# scb register map
Vendor: Texas Instruments
Peripheral module from a debugger description file (folder MSP432).
Registers are 32-bit, read-write, no defined reset value unless marked. A register's access mark holds for its fields unless they carry their own. Offsets are as the file gives them; lines under a group give offsets from that group; [hi:lo] are bit positions; {n}, {i} and the like mark numbered series; 'fields as' and 'values as' point back to an identical list; <NAME> marks a mode.

## SCB
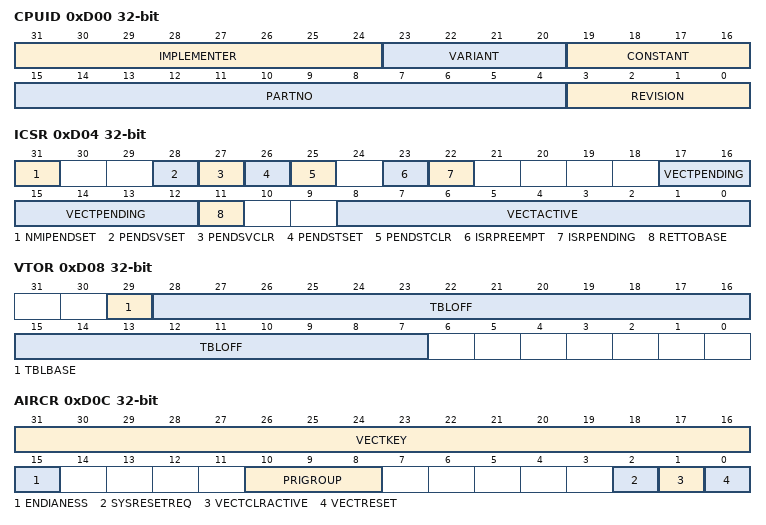
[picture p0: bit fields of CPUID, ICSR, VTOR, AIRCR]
0xD00 CPUID — CPUID Base Register
  [31:24] IMPLEMENTER — Implementor code.
  [23:20] VARIANT — Implementation defined variant number.
  [19:16] CONSTANT — Reads as 0xC
  [15:4] PARTNO — Number of processor within family.
  [3:0] REVISION — Implementation defined revision number.
0xD04 ICSR — Interrupt Control State Register
  [31] NMIPENDSET — Set pending NMI bit
    0=NMIPENDSET__0 (do not set pending NMI); 1=NMIPENDSET__1 (set pending NMI)
  [28] PENDSVSET — Set pending pendSV bit.
    0=PENDSVSET__0 (do not set pending pendSV); 1=PENDSVSET__1 (set pending PendSV)
  [27] PENDSVCLR — Clear pending pendSV bit
    0=PENDSVCLR__0 (do not clear pending pendSV); 1=PENDSVCLR__1 (clear pending pendSV)
  [26] PENDSTSET — Set a pending SysTick bit.
    0=PENDSTSET__0 (do not set pending SysTick); 1=PENDSTSET__1 (set pending SysTick)
  [25] PENDSTCLR — Clear pending SysTick bit
    0=PENDSTCLR__0 (do not clear pending SysTick); 1=PENDSTCLR__1 (clear pending SysTick)
  [23] ISRPREEMPT — You must only use this at debug time
    0=ISRPREEMPT__0 (a pending exception is not serviced.); 1=ISRPREEMPT__1 (a pending exception is serviced on exit from the debug halt sta)
  [22] ISRPENDING — Interrupt pending flag. Excludes NMI and faults.
    0=ISRPENDING__0 (interrupt not pending); 1=ISRPENDING__1 (interrupt pending)
  [17:12] VECTPENDING — Pending ISR number field
  [11] RETTOBASE — This bit is 1 when the set of all active exceptions minus the I
  [8:0] VECTACTIVE — Active ISR number field. Reset clears the VECTACTIVE field.
0xD08 VTOR — Vector Table Offset Register
  [29] TBLBASE — Table base is in Code (0) or RAM (1).
  [28:7] TBLOFF — Vector table base offset field
0xD0C AIRCR — Application Interrupt/Reset Control Register
  [31:16] VECTKEY — Register key
  [15] ENDIANESS — Data endianness bit
    0=ENDIANESS__0 (little endian); 1=ENDIANESS__1 (big endian)
  [10:8] PRIGROUP — Interrupt priority grouping field
  [2] SYSRESETREQ — Causes a signal to be asserted to the outer system that indicat
  [1] VECTCLRACTIVE — Clears all active state information for active NMI, fault, and
  [0] VECTRESET — System Reset bit
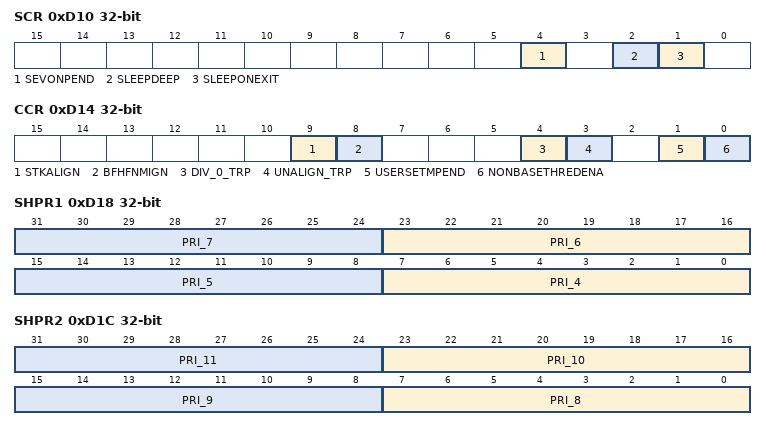
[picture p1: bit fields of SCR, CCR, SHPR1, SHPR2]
0xD10 SCR — System Control Register
  [4] SEVONPEND — When enabled, this causes WFE to wake up when an interrupt move
  [2] SLEEPDEEP — Sleep deep bit.
    0=SLEEPDEEP__0 (not OK to turn off system clock); 1=SLEEPDEEP__1 (indicates to the system that Cortex-M4 clock can be stopped)
  [1] SLEEPONEXIT — Sleep on exit when returning from Handler mode to Thread mode
    0=SLEEPONEXIT__0 (do not sleep when returning to thread mode); 1=SLEEPONEXIT__1 (sleep on ISR exit)
0xD14 CCR — Configuration Control Register
  [9] STKALIGN — Stack alignment bit.
    0=STKALIGN__0 (Only 4-byte alignment is guaranteed for the SP used prior to th); 1=STKALIGN__1 (On exception entry, the SP used prior to the exception is adjus)
  [8] BFHFNMIGN — When enabled, this causes handlers running at priority -1 and -
  [4] DIV_0_TRP — Trap on Divide by 0
  [3] UNALIGN_TRP — Trap for unaligned access
  [1] USERSETMPEND — If written as 1, enables user code to write the Software Trigge
  [0] NONBASETHREDENA — When 0, default, It is only possible to enter Thread mode when
0xD18 SHPR1 — System Handlers 4-7 Priority Register
  [8n-25:8n-32] PRI_{n} (n=4..7) — Priority of system handler {n}.
0xD1C SHPR2 — System Handlers 8-11 Priority Register
  [8n-57:8n-64] PRI_{n} (n=8..11) — Priority of system handler {n}.
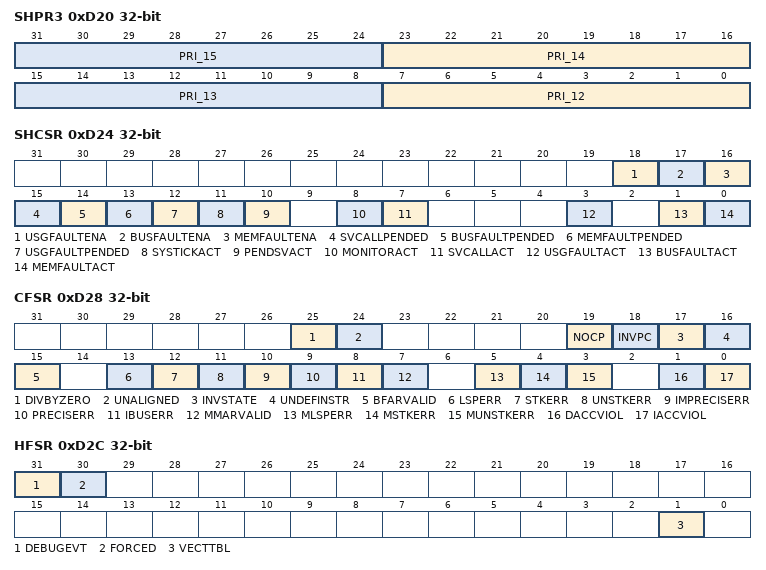
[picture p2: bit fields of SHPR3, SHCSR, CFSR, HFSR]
0xD20 SHPR3 — System Handlers 12-15 Priority Register
  [8n-89:8n-96] PRI_{n} (n=12..15) — Priority of system handler {n}.
0xD24 SHCSR — System Handler Control and State Register
  [18] USGFAULTENA — Usage fault system handler enable
    0=USGFAULTENA__0 (disabled); 1=USGFAULTENA__1 (enabled)
  [17] BUSFAULTENA — Bus fault system handler enable
    0=BUSFAULTENA__0 (disabled); 1=BUSFAULTENA__1 (enabled)
  [16] MEMFAULTENA — MemManage fault system handler enable
    0=MEMFAULTENA__0 (disabled); 1=MEMFAULTENA__1 (enabled)
  [15] SVCALLPENDED — SVCall pended flag.
    0=SVCALLPENDED__0 (not pended); 1=SVCALLPENDED__1 (pended)
  [14] BUSFAULTPENDED — BusFault pended flag.
    0=BUSFAULTPENDED__0 (not pended); 1=BUSFAULTPENDED__1 (pended)
  [13] MEMFAULTPENDED — MemManage pended flag.
    0=MEMFAULTPENDED__0 (not pended); 1=MEMFAULTPENDED__1 (pended)
  [12] USGFAULTPENDED — usage fault pended flag.
    0=USGFAULTPENDED__0 (not pended); 1=USGFAULTPENDED__1 (pended)
  [11] SYSTICKACT — SysTick active flag.
    0=SYSTICKACT__0 (not active); 1=SYSTICKACT__1 (active)
  [10] PENDSVACT — PendSV active flag.
    0=PENDSVACT__0 (not active); 1=PENDSVACT__1 (active)
  [8] MONITORACT — the Monitor active flag.
    0=MONITORACT__0 (not active); 1=MONITORACT__1 (active)
  [7] SVCALLACT — SVCall active flag.
    0=SVCALLACT__0 (not active); 1=SVCALLACT__1 (active)
  [3] USGFAULTACT — UsageFault active flag.
    0=USGFAULTACT__0 (not active); 1=USGFAULTACT__1 (active)
  [1] BUSFAULTACT — BusFault active flag.
    0=BUSFAULTACT__0 (not active); 1=BUSFAULTACT__1 (active)
  [0] MEMFAULTACT — MemManage active flag.
    0=MEMFAULTACT__0 (not active); 1=MEMFAULTACT__1 (active)
0xD28 CFSR — Configurable Fault Status Registers
  [25] DIVBYZERO — When DIV_0_TRP (see Configuration Control Register on page 8-26
  [24] UNALIGNED — When UNALIGN_TRP is enabled (see Configuration Control Register
  [19] NOCP — Attempt to use a coprocessor instruction
  [18] INVPC — Attempt to load EXC_RETURN into PC illegally
  [17] INVSTATE — Invalid combination of EPSR and instruction, for reasons other
  [16] UNDEFINSTR — The UNDEFINSTR flag is set when the processor attempts to execu
  [15] BFARVALID — This bit is set if the Bus Fault Address Register (BFAR) contai
  [13] LSPERR — Indicates if bus fault occurred during FP lazy state preservati
  [12] STKERR — Stacking from exception has caused one or more bus faults
  [11] UNSTKERR — Unstack from exception return has caused one or more bus faults
  [10] IMPRECISERR — Imprecise data bus error
  [9] PRECISERR — Precise data bus error return.
  [8] IBUSERR — Instruction bus error flag
  [7] MMARVALID — Memory Manage Address Register (MMAR) address valid flag
  [5] MLSPERR — Indicates if MemManage fault occurred during FP lazy state pres
  [4] MSTKERR — Stacking from exception has caused one or more access violation
  [3] MUNSTKERR — Unstack from exception return has caused one or more access vio
  [1] DACCVIOL — Data access violation flag
  [0] IACCVIOL — Instruction access violation flag
0xD2C HFSR — Hard Fault Status Register
  [31] DEBUGEVT — This bit is set if there is a fault related to debug
  [30] FORCED — Hard Fault activated because a Configurable Fault was received
  [1] VECTTBL — This bit is set if there is a fault because of vector table rea
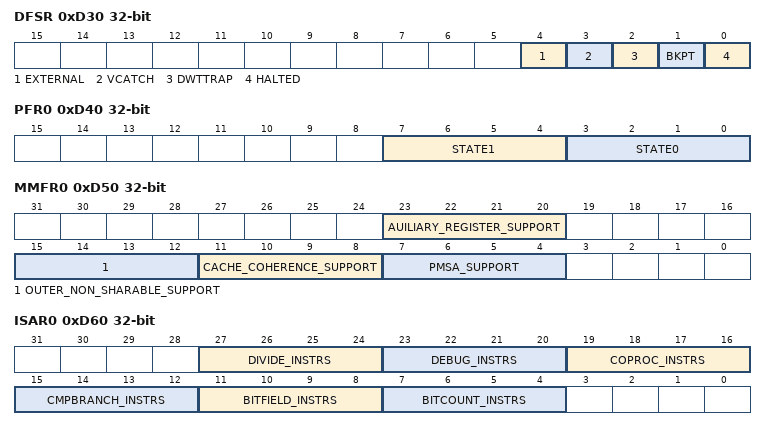
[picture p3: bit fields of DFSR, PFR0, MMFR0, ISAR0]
0xD30 DFSR — Debug Fault Status Register
  [4] EXTERNAL — External debug request flag
    0=EXTERNAL__0 (EDBGRQ signal not asserted); 1=EXTERNAL__1 (EDBGRQ signal asserted)
  [3] VCATCH — Vector catch flag
    0=VCATCH__0 (no vector catch occurred); 1=VCATCH__1 (vector catch occurred)
  [2] DWTTRAP — Data Watchpoint and Trace (DWT) flag
    0=DWTTRAP__0 (no DWT match); 1=DWTTRAP__1 (DWT match)
  [1] BKPT — BKPT flag
    0=BKPT__0 (no BKPT instruction execution); 1=BKPT__1 (BKPT instruction execution)
  [0] HALTED — Halt request flag
    0=HALTED__0 (no halt request); 1=HALTED__1 (halt requested by NVIC, including step)
0xD34 MMFAR — Mem Manage Fault Address Register
  [31:0] ADDRESS — Mem Manage fault address field
0xD38 BFAR — Bus Fault Address Register
  [31:0] ADDRESS — Bus fault address field
0xD3C AFSR — Auxiliary Fault Status Register
  [31:0] IMPDEF — Implementation defined
0xD40 PFR0 — Processor Feature register0
  [7:4] STATE1 — State1 (T-bit == 1)
    0=STATE1__0 (N/A); 1=STATE1__1 (N/A); 2=STATE1__2 (Thumb-2 encoding with the 16-bit basic instructions plus 32-bit); 3=STATE1__3 (Thumb-2 encoding with all Thumb-2 basic instructions)
  [3:0] STATE0 — State0 (T-bit == 0)
    0=STATE0__0 (no ARM encoding); 1=STATE0__1 (N/A)
0xD44 PFR1 — Processor Feature register1
  [11:8] MICROCONTROLLER_PROGRAMMERS_MODEL
    0=MICROCONTROLLER_PROGRAMMERS_MODEL__0 (not supported); 2=MICROCONTROLLER_PROGRAMMERS_MODEL__2 (two-stack support)
0xD48 DFR0 — Debug Feature register0
  [23:20] MICROCONTROLLER_DEBUG_MODEL — Microcontroller Debug Model - memory mapped
    0=MICROCONTROLLER_DEBUG_MODEL__0 (not supported); 1=MICROCONTROLLER_DEBUG_MODEL__1 (Microcontroller debug v1 (ITMv1, DWTv1, optional ETM))
0xD4C AFR0 access not given — Auxiliary Feature register0
0xD50 MMFR0 — Memory Model Feature register0
  [23:20] AUILIARY_REGISTER_SUPPORT — Auxiliary register support
    0=AUILIARY_REGISTER_SUPPORT__0 (not supported); 1=AUILIARY_REGISTER_SUPPORT__1 (Auxiliary control register)
  [15:12] OUTER_NON_SHARABLE_SUPPORT
    0=OUTER_NON_SHARABLE_SUPPORT__0 (Outer non-sharable not supported); 1=OUTER_NON_SHARABLE_SUPPORT__1 (Outer sharable supported)
  [11:8] CACHE_COHERENCE_SUPPORT
    0=CACHE_COHERENCE_SUPPORT__0 (no shared support); 1=CACHE_COHERENCE_SUPPORT__1 (partial-inner-shared coherency (coherency amongst some - but no); 2=CACHE_COHERENCE_SUPPORT__2 (full-inner-shared coherency (coherency amongst all of the entit); 3=CACHE_COHERENCE_SUPPORT__3 (full coherency (coherency amongst all of the entities))
  [7:4] PMSA_SUPPORT
    0=PMSA_SUPPORT__0 (not supported); 1=PMSA_SUPPORT__1 (IMPLEMENTATION DEFINED (N/A)); 2=PMSA_SUPPORT__2 (PMSA base (features as defined for ARMv6) (N/A)); 3=PMSA_SUPPORT__3 (PMSAv7 (base plus subregion support))
0xD54 MMFR1 access not given — Memory Model Feature register1
0xD58 MMFR2 — Memory Model Feature register2
  [27:24] WAIT_FOR_INTERRUPT_STALLING
    0=WAIT_FOR_INTERRUPT_STALLING__0 (not supported); 1=WAIT_FOR_INTERRUPT_STALLING__1 (wait for interrupt supported)
0xD5C MMFR3 access not given — Memory Model Feature register3
0xD60 ISAR0 — ISA Feature register0
  [27:24] DIVIDE_INSTRS — Divide instructions
    0=DIVIDE_INSTRS__0 (no divide instructions present); 1=DIVIDE_INSTRS__1 (adds SDIV, UDIV (v1 quotient only result))
  [23:20] DEBUG_INSTRS — Debug instructions
    0=DEBUG_INSTRS__0 (no debug instructions present); 1=DEBUG_INSTRS__1 (adds BKPT)
  [19:16] COPROC_INSTRS — Coprocessor instructions
    0=COPROC_INSTRS__0 (no coprocessor support, other than for separately attributed ar); 1=COPROC_INSTRS__1 (adds generic CDP, LDC, MCR, MRC, STC); 2=COPROC_INSTRS__2 (adds generic CDP2, LDC2, MCR2, MRC2, STC2); 3=COPROC_INSTRS__3 (adds generic MCRR, MRRC); 4=COPROC_INSTRS__4 (adds generic MCRR2, MRRC2)
  [15:12] CMPBRANCH_INSTRS — CmpBranch instructions
    0=CMPBRANCH_INSTRS__0 (no combined compare-and-branch instructions present); 1=CMPBRANCH_INSTRS__1 (adds CB{N}Z)
  [11:8] BITFIELD_INSTRS — BitField instructions
    0=BITFIELD_INSTRS__0 (no bitfield instructions present); 1=BITFIELD_INSTRS__1 (adds BFC, BFI, SBFX, UBFX)
  [7:4] BITCOUNT_INSTRS — BitCount instructions
    0=BITCOUNT_INSTRS__0 (no bit-counting instructions present); 1=BITCOUNT_INSTRS__1 (adds CLZ)
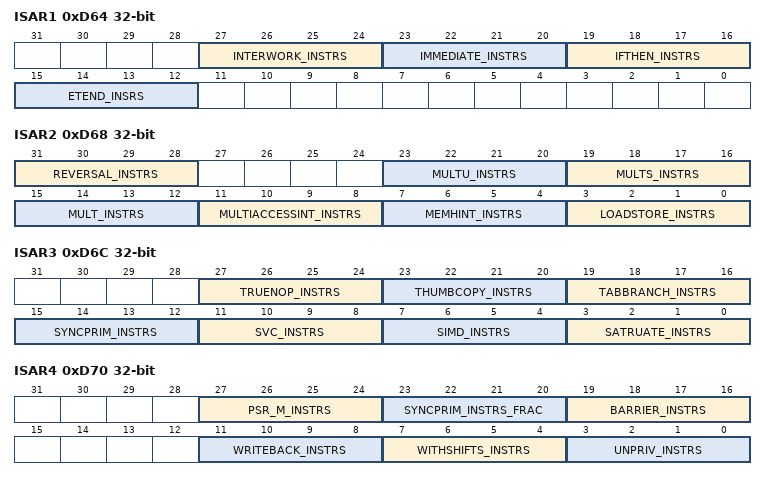
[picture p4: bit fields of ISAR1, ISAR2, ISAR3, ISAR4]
0xD64 ISAR1 — ISA Feature register1
  [27:24] INTERWORK_INSTRS — Interwork instructions
    0=INTERWORK_INSTRS__0 (no interworking instructions supported); 1=INTERWORK_INSTRS__1 (adds BX (and T bit in PSRs)); 2=INTERWORK_INSTRS__2 (adds BLX, and PC loads have BX-like behavior); 3=INTERWORK_INSTRS__3 (N/A)
  [23:20] IMMEDIATE_INSTRS — Immediate instructions
    0=IMMEDIATE_INSTRS__0 (no special immediate-generating instructions present); 1=IMMEDIATE_INSTRS__1 (adds ADDW, MOVW, MOVT, SUBW)
  [19:16] IFTHEN_INSTRS — IfThen instructions
    0=IFTHEN_INSTRS__0 (IT instructions not present); 1=IFTHEN_INSTRS__1 (adds IT instructions (and IT bits in PSRs))
  [15:12] ETEND_INSRS — Extend instructions
    0=ETEND_INSRS__0 (no scalar (i.e. non-SIMD) sign/zero-extend instructions present); 1=ETEND_INSRS__1 (adds SXTB, SXTH, UXTB, UXTH); 2=ETEND_INSRS__2 (N/A)
0xD68 ISAR2 — ISA Feature register2
  [31:28] REVERSAL_INSTRS — Reversal instructions
    0=REVERSAL_INSTRS__0 (no reversal instructions present); 1=REVERSAL_INSTRS__1 (adds REV, REV16, REVSH); 2=REVERSAL_INSTRS__2 (adds RBIT)
  [23:20] MULTU_INSTRS — Multiply instructions (advanced, unsigned)
    0=MULTU_INSTRS__0 (no unsigned multiply instructions present); 1=MULTU_INSTRS__1 (adds UMULL, UMLAL); 2=MULTU_INSTRS__2 (N/A)
  [19:16] MULTS_INSTRS — Multiply instructions (advanced, signed)
    0=MULTS_INSTRS__0 (no signed multiply instructions present); 1=MULTS_INSTRS__1 (adds SMULL, SMLAL); 2=MULTS_INSTRS__2 (N/A); 3=MULTS_INSTRS__3 (N/A)
  [15:12] MULT_INSTRS — Multiply instructions
    0=MULT_INSTRS__0 (only MUL present); 1=MULT_INSTRS__1 (adds MLA); 2=MULT_INSTRS__2 (adds MLS)
  [11:8] MULTIACCESSINT_INSTRS — Multi-Access interruptible instructions
    0=MULTIACCESSINT_INSTRS__0 (the (LDM/STM) instructions are non-interruptible); 1=MULTIACCESSINT_INSTRS__1 (the (LDM/STM) instructions are restartable); 2=MULTIACCESSINT_INSTRS__2 (the (LDM/STM) instructions are continuable)
  [7:4] MEMHINT_INSTRS — MemoryHint instructions
    0=MEMHINT_INSTRS__0 (no memory hint instructions presen); 1=MEMHINT_INSTRS__1 (adds PLD); 2=MEMHINT_INSTRS__2 (adds PLD (ie a repeat on value 1)); 3=MEMHINT_INSTRS__3 (adds PLI)
  [3:0] LOADSTORE_INSTRS — LoadStore instructions
    0=LOADSTORE_INSTRS__0 (no additional normal load/store instructions present); 1=LOADSTORE_INSTRS__1 (adds LDRD/STRD)
0xD6C ISAR3 — ISA Feature register3
  [27:24] TRUENOP_INSTRS — TrueNOP instructions
    0=TRUENOP_INSTRS__0 (true NOP instructions not present - that is, NOP instructions w); 1=TRUENOP_INSTRS__1 (adds "true NOP", and the capability of additional "NOP compatib)
  [23:20] THUMBCOPY_INSTRS — ThumbCopy instructions
    0=THUMBCOPY_INSTRS__0 (Thumb MOV(register) instruction does not allow low reg -> low r); 1=THUMBCOPY_INSTRS__1 (adds Thumb MOV(register) low reg -> low reg and the CPY alias)
  [19:16] TABBRANCH_INSTRS — TableBranch instructions
    0=TABBRANCH_INSTRS__0 (no table-branch instructions present); 1=TABBRANCH_INSTRS__1 (adds TBB, TBH)
  [15:12] SYNCPRIM_INSTRS — SyncPrim instructions
    0=SYNCPRIM_INSTRS__0 (no synchronization primitives present); 1=SYNCPRIM_INSTRS__1 (adds LDREX, STREX); 2=SYNCPRIM_INSTRS__2 (adds LDREXB, LDREXH, LDREXD, STREXB, STREXH, STREXD, CLREX(N/A))
  [11:8] SVC_INSTRS — SVC instructions
    0=SVC_INSTRS__0 (no SVC (SWI) instructions present); 1=SVC_INSTRS__1 (adds SVC (SWI))
  [7:4] SIMD_INSTRS — SIMD instructions
    0=SIMD_INSTRS__0 (no SIMD instructions present); 1=SIMD_INSTRS__1 (adds SSAT, USAT (and the Q flag in the PSRs)); 3=SIMD_INSTRS__3 (N/A)
  [3:0] SATRUATE_INSTRS — Saturate instructions
    0=SATRUATE_INSTRS__0 (no non-SIMD saturate instructions present); 1=SATRUATE_INSTRS__1 (N/A)
0xD70 ISAR4 — ISA Feature register4
  [27:24] PSR_M_INSTRS
    0=PSR_M_INSTRS__0 (instructions not present); 1=PSR_M_INSTRS__1 (adds CPS, MRS, and MSR instructions (M-profile forms))
  [23:20] SYNCPRIM_INSTRS_FRAC
    0=SYNCPRIM_INSTRS_FRAC__0 (no additional support); 3=SYNCPRIM_INSTRS_FRAC__3 (adds CLREX, LDREXB, STREXB, LDREXH, STREXH)
  [19:16] BARRIER_INSTRS — Barrier instructions
    0=BARRIER_INSTRS__0 (no barrier instructions supported); 1=BARRIER_INSTRS__1 (adds DMB, DSB, ISB barrier instructions)
  [11:8] WRITEBACK_INSTRS — Writeback instructions
    0=WRITEBACK_INSTRS__0 (only non-writeback addressing modes present, except that LDMIA/); 1=WRITEBACK_INSTRS__1 (adds all currently-defined writeback addressing modes (ARMv7, T)
  [7:4] WITHSHIFTS_INSTRS — WithShift instructions
    0=WITHSHIFTS_INSTRS__0 (non-zero shifts only support MOV and shift instructions (see no); 1=WITHSHIFTS_INSTRS__1 (shifts of loads/stores over the range LSL 0-3); 3=WITHSHIFTS_INSTRS__3 (adds other constant shift options.); 4=WITHSHIFTS_INSTRS__4 (adds register-controlled shift options.)
  [3:0] UNPRIV_INSTRS — Unprivileged instructions
    0=UNPRIV_INSTRS__0 (no "T variant" instructions exist); 1=UNPRIV_INSTRS__1 (adds LDRBT, LDRT, STRBT, STRT); 2=UNPRIV_INSTRS__2 (adds LDRHT, LDRSBT, LDRSHT, STRHT)
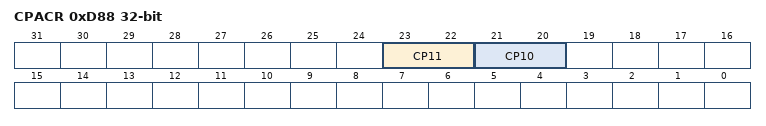
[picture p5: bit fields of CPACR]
0xD88 CPACR — Coprocessor Access Control Register
  [23:22] CP11 — Access privileges for coprocessor 11
  [21:20] CP10 — Access privileges for coprocessor 10
